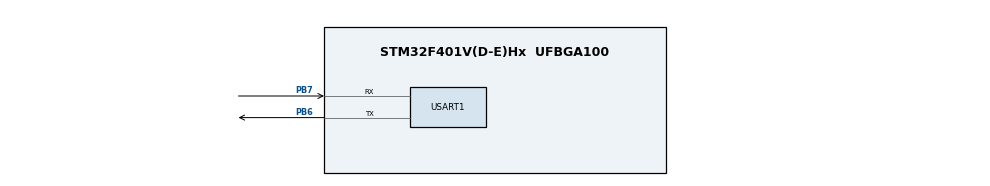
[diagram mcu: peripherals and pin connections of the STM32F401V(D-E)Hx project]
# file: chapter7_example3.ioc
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Dma.Request0=USART1_TX
Dma.USART1_TX.0.Direction=DMA_MEMORY_TO_PERIPH
Dma.USART1_TX.0.FIFOMode=DMA_FIFOMODE_DISABLE
Dma.USART1_TX.0.Instance=DMA2_Stream7
Dma.USART1_TX.0.MemDataAlignment=DMA_MDATAALIGN_BYTE
Dma.USART1_TX.0.MemInc=DMA_MINC_ENABLE
Dma.USART1_TX.0.Mode=DMA_NORMAL
Dma.USART1_TX.0.PeriphDataAlignment=DMA_PDATAALIGN_BYTE
Dma.USART1_TX.0.PeriphInc=DMA_PINC_DISABLE
Dma.USART1_TX.0.Priority=DMA_PRIORITY_LOW
Mcu.Family=STM32F4
Mcu.Name=STM32F401V(D-E)Hx
Mcu.Package=UFBGA100
NVIC.DMA2_Stream7_IRQn=true\:0\:0\:false\:false\:true\:false\:true\:true
NVIC.PriorityGroup=NVIC_PRIORITYGROUP_4
PB6.Mode=Asynchronous
PB6.Signal=USART1_TX
PB7.Mode=Asynchronous
PB7.Signal=USART1_RX
ProjectManager.HeapSize=0x200
ProjectManager.StackSize=0x400
ProjectManager.TargetToolchain=STM32CubeIDE
RCC.AHBFreq_Value=16000000
RCC.APB1Freq_Value=16000000
RCC.APB2Freq_Value=16000000
RCC.CortexFreq_Value=16000000
RCC.HSE_VALUE=25000000
RCC.HSI_VALUE=16000000
RCC.LSE_VALUE=32768
RCC.SYSCLKFreq_VALUE=16000000
RCC.VCOOutputFreq_Value=192000000
USART1.VirtualMode=VM_ASYNC
board=custom

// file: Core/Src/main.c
/* USER CODE BEGIN Header */
/**
  ******************************************************************************
  * @file           : main.c
  * @brief          : Main program body
  ******************************************************************************
  * @attention
  *
  * Copyright (c) 2025 STMicroelectronics.
  * All rights reserved.
  *
  * This software is licensed under terms that can be found in the LICENSE file
  * in the root directory of this software component.
  * If no LICENSE file comes with this software, it is provided AS-IS.
  *
  ******************************************************************************
  */
/* USER CODE END Header */
#include "main.h"

void SystemClock_Config(void);
static void MX_GPIO_Init(void);
static void MX_DMA_Init(void);
static void MX_USART1_UART_Init(void);

/* USER CODE BEGIN 0 */
void USART1_SendString_DMA(const char *str) ;

/* USER CODE END 0 */

int main(void)
{

  /* MCU Configuration--------------------------------------------------------*/

  /* Reset of all peripherals, Initializes the Flash interface and the Systick. */
  HAL_Init();

  /* Configure the system clock */
  SystemClock_Config();

  /* Initialize all configured peripherals */
  MX_GPIO_Init();
  MX_DMA_Init();
  MX_USART1_UART_Init();

  /* Infinite loop */
  /* USER CODE BEGIN WHILE */
  while (1)
  {
		 USART1_SendString_DMA("Hello by DMA \r\n");
//	  	  while(!LL_USART_IsActiveFlag_TXE(USART1));
//	  	  LL_USART_TransmitData8(USART1, 'A');
	      LL_mDelay(1000);

    /* USER CODE END WHILE */

  }
}

void SystemClock_Config(void)
{
  LL_FLASH_SetLatency(LL_FLASH_LATENCY_0);
  while(LL_FLASH_GetLatency()!= LL_FLASH_LATENCY_0)
  {
  }
  LL_PWR_SetRegulVoltageScaling(LL_PWR_REGU_VOLTAGE_SCALE2);
  LL_RCC_HSI_SetCalibTrimming(16);
  LL_RCC_HSI_Enable();

   /* Wait till HSI is ready */
  while(LL_RCC_HSI_IsReady() != 1)
  {

  }
  LL_RCC_SetAHBPrescaler(LL_RCC_SYSCLK_DIV_1);
  LL_RCC_SetAPB1Prescaler(LL_RCC_APB1_DIV_1);
  LL_RCC_SetAPB2Prescaler(LL_RCC_APB2_DIV_1);
  LL_RCC_SetSysClkSource(LL_RCC_SYS_CLKSOURCE_HSI);

   /* Wait till System clock is ready */
  while(LL_RCC_GetSysClkSource() != LL_RCC_SYS_CLKSOURCE_STATUS_HSI)
  {

  }
  LL_SetSystemCoreClock(16000000);

   /* Update the time base */
  if (HAL_InitTick (TICK_INT_PRIORITY) != HAL_OK)
  {
    Error_Handler();
  }
  LL_RCC_SetTIMPrescaler(LL_RCC_TIM_PRESCALER_TWICE);
}

static void MX_USART1_UART_Init(void)
{

  LL_USART_InitTypeDef USART_InitStruct = {0};

  LL_GPIO_InitTypeDef GPIO_InitStruct = {0};

  /* Peripheral clock enable */
  LL_APB2_GRP1_EnableClock(LL_APB2_GRP1_PERIPH_USART1);

  LL_AHB1_GRP1_EnableClock(LL_AHB1_GRP1_PERIPH_GPIOB);
  /**USART1 GPIO Configuration
  PB7   ------> USART1_RX
  PB6   ------> USART1_TX
  */
  GPIO_InitStruct.Pin = LL_GPIO_PIN_7|LL_GPIO_PIN_6;
  GPIO_InitStruct.Mode = LL_GPIO_MODE_ALTERNATE;
  GPIO_InitStruct.Speed = LL_GPIO_SPEED_FREQ_VERY_HIGH;
  GPIO_InitStruct.OutputType = LL_GPIO_OUTPUT_PUSHPULL;
  GPIO_InitStruct.Pull = LL_GPIO_PULL_NO;
  GPIO_InitStruct.Alternate = LL_GPIO_AF_7;
  LL_GPIO_Init(GPIOB, &GPIO_InitStruct);

  /* USART1 DMA Init */

  /* USART1_TX Init */
  LL_DMA_SetChannelSelection(DMA2, LL_DMA_STREAM_7, LL_DMA_CHANNEL_4);

  LL_DMA_SetDataTransferDirection(DMA2, LL_DMA_STREAM_7, LL_DMA_DIRECTION_MEMORY_TO_PERIPH);

  LL_DMA_SetStreamPriorityLevel(DMA2, LL_DMA_STREAM_7, LL_DMA_PRIORITY_LOW);

  LL_DMA_SetMode(DMA2, LL_DMA_STREAM_7, LL_DMA_MODE_NORMAL);

  LL_DMA_SetPeriphIncMode(DMA2, LL_DMA_STREAM_7, LL_DMA_PERIPH_NOINCREMENT);

  LL_DMA_SetMemoryIncMode(DMA2, LL_DMA_STREAM_7, LL_DMA_MEMORY_INCREMENT);

  LL_DMA_SetPeriphSize(DMA2, LL_DMA_STREAM_7, LL_DMA_PDATAALIGN_BYTE);

  LL_DMA_SetMemorySize(DMA2, LL_DMA_STREAM_7, LL_DMA_MDATAALIGN_BYTE);

  LL_DMA_DisableFifoMode(DMA2, LL_DMA_STREAM_7);

  USART_InitStruct.BaudRate = 115200;
  USART_InitStruct.DataWidth = LL_USART_DATAWIDTH_8B;
  USART_InitStruct.StopBits = LL_USART_STOPBITS_1;
  USART_InitStruct.Parity = LL_USART_PARITY_NONE;
  USART_InitStruct.TransferDirection = LL_USART_DIRECTION_TX_RX;
  USART_InitStruct.HardwareFlowControl = LL_USART_HWCONTROL_NONE;
  USART_InitStruct.OverSampling = LL_USART_OVERSAMPLING_16;
  LL_USART_Init(USART1, &USART_InitStruct);
  LL_USART_ConfigAsyncMode(USART1);
  LL_USART_Enable(USART1);

}

static void MX_DMA_Init(void)
{

  /* DMA controller clock enable */
  __HAL_RCC_DMA2_CLK_ENABLE();

  /* DMA interrupt init */
  /* DMA2_Stream7_IRQn interrupt configuration */
  NVIC_SetPriority(DMA2_Stream7_IRQn, NVIC_EncodePriority(NVIC_GetPriorityGrouping(),0, 0));
  NVIC_EnableIRQ(DMA2_Stream7_IRQn);

}

static void MX_GPIO_Init(void)
{

  /* GPIO Ports Clock Enable */
  LL_AHB1_GRP1_EnableClock(LL_AHB1_GRP1_PERIPH_GPIOB);

}

/* USER CODE BEGIN 4 */
void USART1_SendString_DMA(const char *str) {
    uint16_t length = 0;

    // Tính độ dài chuỗi
    while (str[length] != '\0') {
        length++;
    }

    // Đảm bảo DMA không đang hoạt động
    while (LL_DMA_IsEnabledStream(DMA2, LL_DMA_STREAM_7));

    // Cấu hình DMA để truyền chuỗi
    LL_DMA_SetMemoryAddress(DMA2, LL_DMA_STREAM_7, (uint32_t)str);
    LL_DMA_SetDataLength(DMA2, LL_DMA_STREAM_7, length);

    // Bật DMA Stream
    LL_DMA_EnableStream(DMA2, LL_DMA_STREAM_7);
}
void
DMA2_Stream7_IRQHandler(void) {
    /* Check half-transfer complete interrupt */
//    if (LL_DMA_IsEnabledIT_HT(DMA2, LL_DMA_STREAM_2) && LL_DMA_IsActiveFlag_HT2(DMA2)) {
//        LL_DMA_ClearFlag_HT1(DMA2);             /* CLear half-transfer complete flag */
//        usart_rx_check();                       /* Check for data to process */
//    }

    /* Check transfer-complete interrupt */
    if (LL_DMA_IsEnabledIT_TC(DMA2, LL_DMA_STREAM_2) && LL_DMA_IsActiveFlag_TC2(DMA2)) {
        LL_DMA_ClearFlag_TC1(DMA2);             /* CLear half-transfer complete flag */
//        usart_rx_check();                       /* Check for data to process */
    }

/* Possibly implement other events if needed */
}

/* USER CODE END 4 */

void Error_Handler(void)
{
  __disable_irq();
  while (1)
  {
  }
}
